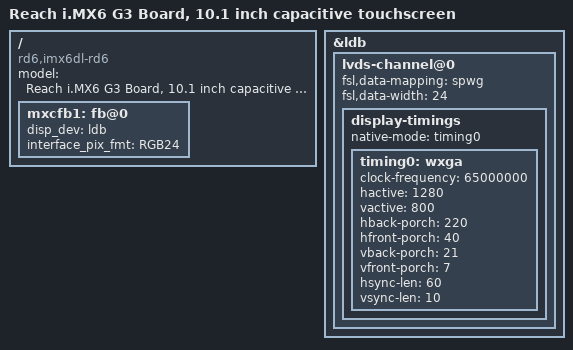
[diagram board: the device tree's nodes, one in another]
/*
 * Copyright 2020 Reach Technology.
 *
 * This program is free software; you can redistribute it and/or modify
 * it under the terms of the GNU General Public License version 2 as
 * published by the Free Software Foundation.
 *
 */
/dts-v1/;
#include "imx6dl.dtsi"
#include "imx6qdl-g3.dtsi"

/ {
    
	model = "Reach i.MX6 G3 Board, 10.1 inch capacitive touchscreen";
	compatible = "rd6,imx6dl-rd6", "fsl,imx6dl";

	mxcfb1: fb@0 {
		disp_dev = "ldb";
		interface_pix_fmt = "RGB24";
		status = "okay";
	};
};

&ldb {
	status = "okay";

	lvds-channel@0 {
		fsl,data-mapping = "spwg";
		fsl,data-width = <24>;
		status = "okay";

		display-timings {
			native-mode = <&timing0>;
			timing0: wxga {
				clock-frequency = <65000000>;
				hactive = <1280>;
				vactive = <800>;
				hback-porch = <220>;
				hfront-porch = <40>;
				vback-porch = <21>;
				vfront-porch = <7>;
				hsync-len = <60>;
				vsync-len = <10>;
			};
		};
	};
};
